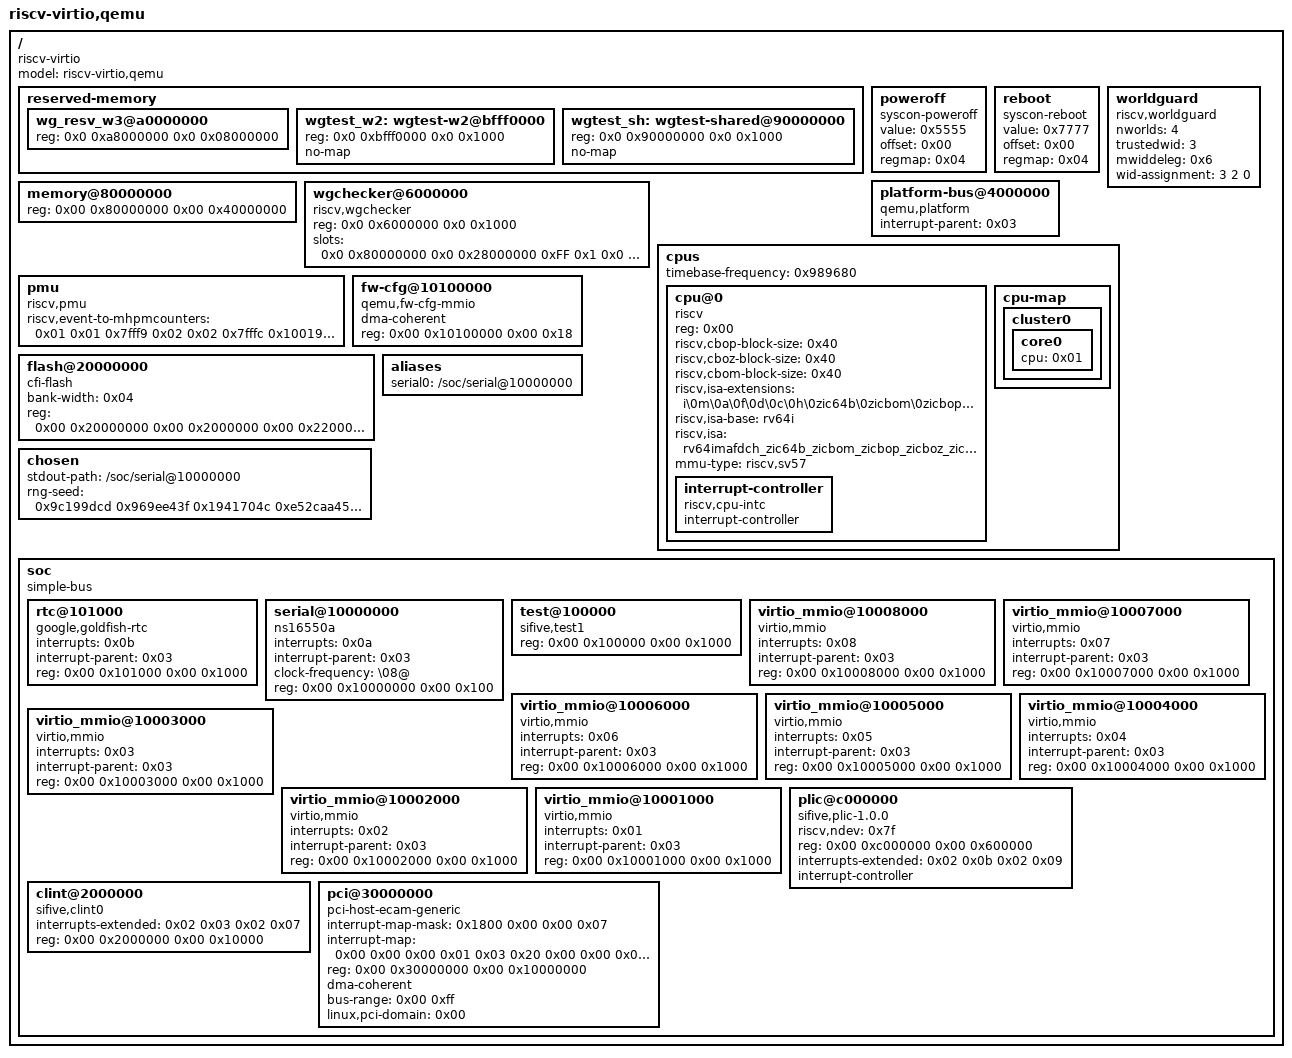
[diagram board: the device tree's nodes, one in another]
/dts-v1/;

/ {
	#address-cells = <0x02>;
	#size-cells = <0x02>;
	compatible = "riscv-virtio";
	model = "riscv-virtio,qemu";

	reserved-memory {
		#address-cells = <0x02>;
		#size-cells = <0x02>;
		ranges;

		/*
		 * Keep WorldGuard-inaccessible DRAM ranges out of Linux allocations
		 * when Linux runs as WID=2 (S-mode).
		 *
		 * Do not use "no-map" here.
		 */
		wg_resv_w3@a0000000 {
			/* World 3 region: [0xA8000000, 0xB0000000) */
			reg = <0x0 0xa8000000 0x0 0x08000000>;
		};

		/*
		 * WorldGuard test scratch pages.
		 *
		 * Keep these pages out of the Linux buddy allocator so user-space can
		 * safely write/read them when exercising U-mode WID restrictions.
		 */
		wgtest_w2: wgtest-w2@bfff0000 {
			reg = <0x0 0xbfff0000 0x0 0x1000>;
			no-map;
		};
		wgtest_sh: wgtest-shared@90000000 {
			reg = <0x0 0x90000000 0x0 0x1000>;
			no-map;
		};
	};

	poweroff {
		value = <0x5555>;
		offset = <0x00>;
		regmap = <0x04>;
		compatible = "syscon-poweroff";
	};

	reboot {
		value = <0x7777>;
		offset = <0x00>;
		regmap = <0x04>;
		compatible = "syscon-reboot";
	};

	platform-bus@4000000 {
		interrupt-parent = <0x03>;
		ranges = <0x00 0x00 0x4000000 0x2000000>;
		#address-cells = <0x01>;
		#size-cells = <0x01>;
		compatible = "qemu,platform\0simple-bus";
	};

	memory@80000000 {
		device_type = "memory";
		/* 1 GiB: [0x80000000, 0xc0000000) covers shared+W3+W2 worlds */
		reg = <0x00 0x80000000 0x00 0x40000000>;
	};

	worldguard {
		compatible = "riscv,worldguard";
		nworlds = <4>;
		trustedwid = <3>;
		mwiddeleg = <0x6>;
		wid-assignment = <3 2 0>;
		status = "okay";
	};

	wgchecker@6000000 {
		compatible = "riscv,wgchecker";
		reg = <0x0 0x6000000 0x0 0x1000>;
		slots = <
			/* Shared: keep initrd in shared (QEMU places it at ~kernel+512MiB) */
			0x0 0x80000000 0x0 0x28000000 0xFF 0x1
			0x0 0xA8000000 0x0 0x08000000 0xC3 0x1
			0x0 0xB0000000 0x0 0x10000000 0xF3 0x1
			0x0 0xC0000000 0x0 0x10000000 0xCF 0x1
			0x0 0xD0000000 0x0 0x30000000 0xC3 0x1
		>;
		status = "okay";
	};

	cpus {
		#address-cells = <0x01>;
		#size-cells = <0x00>;
		timebase-frequency = <0x989680>;

		cpu@0 {
			phandle = <0x01>;
			device_type = "cpu";
			reg = <0x00>;
			status = "okay";
			compatible = "riscv";
			riscv,cbop-block-size = <0x40>;
			riscv,cboz-block-size = <0x40>;
			riscv,cbom-block-size = <0x40>;
			riscv,isa-extensions = "i\0m\0a\0f\0d\0c\0h\0zic64b\0zicbom\0zicbop\0zicboz\0ziccamoa\0ziccif\0zicclsm\0ziccrse\0zicntr\0zicsr\0zifencei\0zihintntl\0zihintpause\0zihpm\0zmmul\0za64rs\0zaamo\0zalrsc\0zawrs\0zfa\0zca\0zcd\0zba\0zbb\0zbc\0zbs\0sdtrig\0shcounterenw\0shgatpa\0shtvala\0shvsatpa\0shvstvala\0shvstvecd\0smwg\0ssccptr\0sscounterenw\0ssstrict\0sstc\0sstvala\0sstvecd\0ssu64xl\0sswg\0svadu\0svvptc";
			riscv,isa-base = "rv64i";
			riscv,isa = "rv64imafdch_zic64b_zicbom_zicbop_zicboz_ziccamoa_ziccif_zicclsm_ziccrse_zicntr_zicsr_zifencei_zihintntl_zihintpause_zihpm_zmmul_za64rs_zaamo_zalrsc_zawrs_zfa_zca_zcd_zba_zbb_zbc_zbs_sdtrig_shcounterenw_shgatpa_shtvala_shvsatpa_shvstvala_shvstvecd_smwg_ssccptr_sscounterenw_ssstrict_sstc_sstvala_sstvecd_ssu64xl_sswg_svadu_svvptc";
			mmu-type = "riscv,sv57";

			interrupt-controller {
				#interrupt-cells = <0x01>;
				interrupt-controller;
				compatible = "riscv,cpu-intc";
				phandle = <0x02>;
			};
		};

		cpu-map {
			cluster0 {
				core0 {
					cpu = <0x01>;
				};
			};
		};
	};

	pmu {
		riscv,event-to-mhpmcounters = <0x01 0x01 0x7fff9 0x02 0x02 0x7fffc 0x10019 0x10019 0x7fff8 0x1001b 0x1001b 0x7fff8 0x10021 0x10021 0x7fff8>;
		compatible = "riscv,pmu";
	};

	fw-cfg@10100000 {
		dma-coherent;
		reg = <0x00 0x10100000 0x00 0x18>;
		compatible = "qemu,fw-cfg-mmio";
	};

	flash@20000000 {
		bank-width = <0x04>;
		reg = <0x00 0x20000000 0x00 0x2000000 0x00 0x22000000 0x00 0x2000000>;
		compatible = "cfi-flash";
	};

	aliases {
		serial0 = "/soc/serial@10000000";
	};

	chosen {
		stdout-path = "/soc/serial@10000000";
		rng-seed = <0x9c199dcd 0x969ee43f 0x1941704c 0xe52caa45 0x82ea0ac4 0xef41b287 0xc3965c0f 0xbd8670f8>;
	};

	soc {
		#address-cells = <0x02>;
		#size-cells = <0x02>;
		compatible = "simple-bus";
		ranges;

		rtc@101000 {
			interrupts = <0x0b>;
			interrupt-parent = <0x03>;
			reg = <0x00 0x101000 0x00 0x1000>;
			compatible = "google,goldfish-rtc";
		};

		serial@10000000 {
			interrupts = <0x0a>;
			interrupt-parent = <0x03>;
			clock-frequency = "\08@";
			reg = <0x00 0x10000000 0x00 0x100>;
			compatible = "ns16550a";
		};

		test@100000 {
			phandle = <0x04>;
			reg = <0x00 0x100000 0x00 0x1000>;
			compatible = "sifive,test1\0sifive,test0\0syscon";
		};

		virtio_mmio@10008000 {
			interrupts = <0x08>;
			interrupt-parent = <0x03>;
			reg = <0x00 0x10008000 0x00 0x1000>;
			compatible = "virtio,mmio";
		};

		virtio_mmio@10007000 {
			interrupts = <0x07>;
			interrupt-parent = <0x03>;
			reg = <0x00 0x10007000 0x00 0x1000>;
			compatible = "virtio,mmio";
		};

		virtio_mmio@10006000 {
			interrupts = <0x06>;
			interrupt-parent = <0x03>;
			reg = <0x00 0x10006000 0x00 0x1000>;
			compatible = "virtio,mmio";
		};

		virtio_mmio@10005000 {
			interrupts = <0x05>;
			interrupt-parent = <0x03>;
			reg = <0x00 0x10005000 0x00 0x1000>;
			compatible = "virtio,mmio";
		};

		virtio_mmio@10004000 {
			interrupts = <0x04>;
			interrupt-parent = <0x03>;
			reg = <0x00 0x10004000 0x00 0x1000>;
			compatible = "virtio,mmio";
		};

		virtio_mmio@10003000 {
			interrupts = <0x03>;
			interrupt-parent = <0x03>;
			reg = <0x00 0x10003000 0x00 0x1000>;
			compatible = "virtio,mmio";
		};

		virtio_mmio@10002000 {
			interrupts = <0x02>;
			interrupt-parent = <0x03>;
			reg = <0x00 0x10002000 0x00 0x1000>;
			compatible = "virtio,mmio";
		};

		virtio_mmio@10001000 {
			interrupts = <0x01>;
			interrupt-parent = <0x03>;
			reg = <0x00 0x10001000 0x00 0x1000>;
			compatible = "virtio,mmio";
		};

		plic@c000000 {
			phandle = <0x03>;
			riscv,ndev = <0x7f>;
			reg = <0x00 0xc000000 0x00 0x600000>;
			interrupts-extended = <0x02 0x0b 0x02 0x09>;
			interrupt-controller;
			compatible = "sifive,plic-1.0.0\0riscv,plic0";
			#address-cells = <0x00>;
			#interrupt-cells = <0x01>;
		};

		clint@2000000 {
			interrupts-extended = <0x02 0x03 0x02 0x07>;
			reg = <0x00 0x2000000 0x00 0x10000>;
			compatible = "sifive,clint0\0riscv,clint0";
		};

		pci@30000000 {
			interrupt-map-mask = <0x1800 0x00 0x00 0x07>;
			interrupt-map = <0x00 0x00 0x00 0x01 0x03 0x20 0x00 0x00 0x00 0x02 0x03 0x21 0x00 0x00 0x00 0x03 0x03 0x22 0x00 0x00 0x00 0x04 0x03 0x23 0x800 0x00 0x00 0x01 0x03 0x21 0x800 0x00 0x00 0x02 0x03 0x22 0x800 0x00 0x00 0x03 0x03 0x23 0x800 0x00 0x00 0x04 0x03 0x20 0x1000 0x00 0x00 0x01 0x03 0x22 0x1000 0x00 0x00 0x02 0x03 0x23 0x1000 0x00 0x00 0x03 0x03 0x20 0x1000 0x00 0x00 0x04 0x03 0x21 0x1800 0x00 0x00 0x01 0x03 0x23 0x1800 0x00 0x00 0x02 0x03 0x20 0x1800 0x00 0x00 0x03 0x03 0x21 0x1800 0x00 0x00 0x04 0x03 0x22>;
			ranges = <0x1000000 0x00 0x00 0x00 0x3000000 0x00 0x10000 0x2000000 0x00 0x40000000 0x00 0x40000000 0x00 0x40000000 0x3000000 0x04 0x00 0x04 0x00 0x04 0x00>;
			reg = <0x00 0x30000000 0x00 0x10000000>;
			dma-coherent;
			bus-range = <0x00 0xff>;
			linux,pci-domain = <0x00>;
			device_type = "pci";
			compatible = "pci-host-ecam-generic";
			#size-cells = <0x02>;
			#interrupt-cells = <0x01>;
			#address-cells = <0x03>;
		};
	};
};
